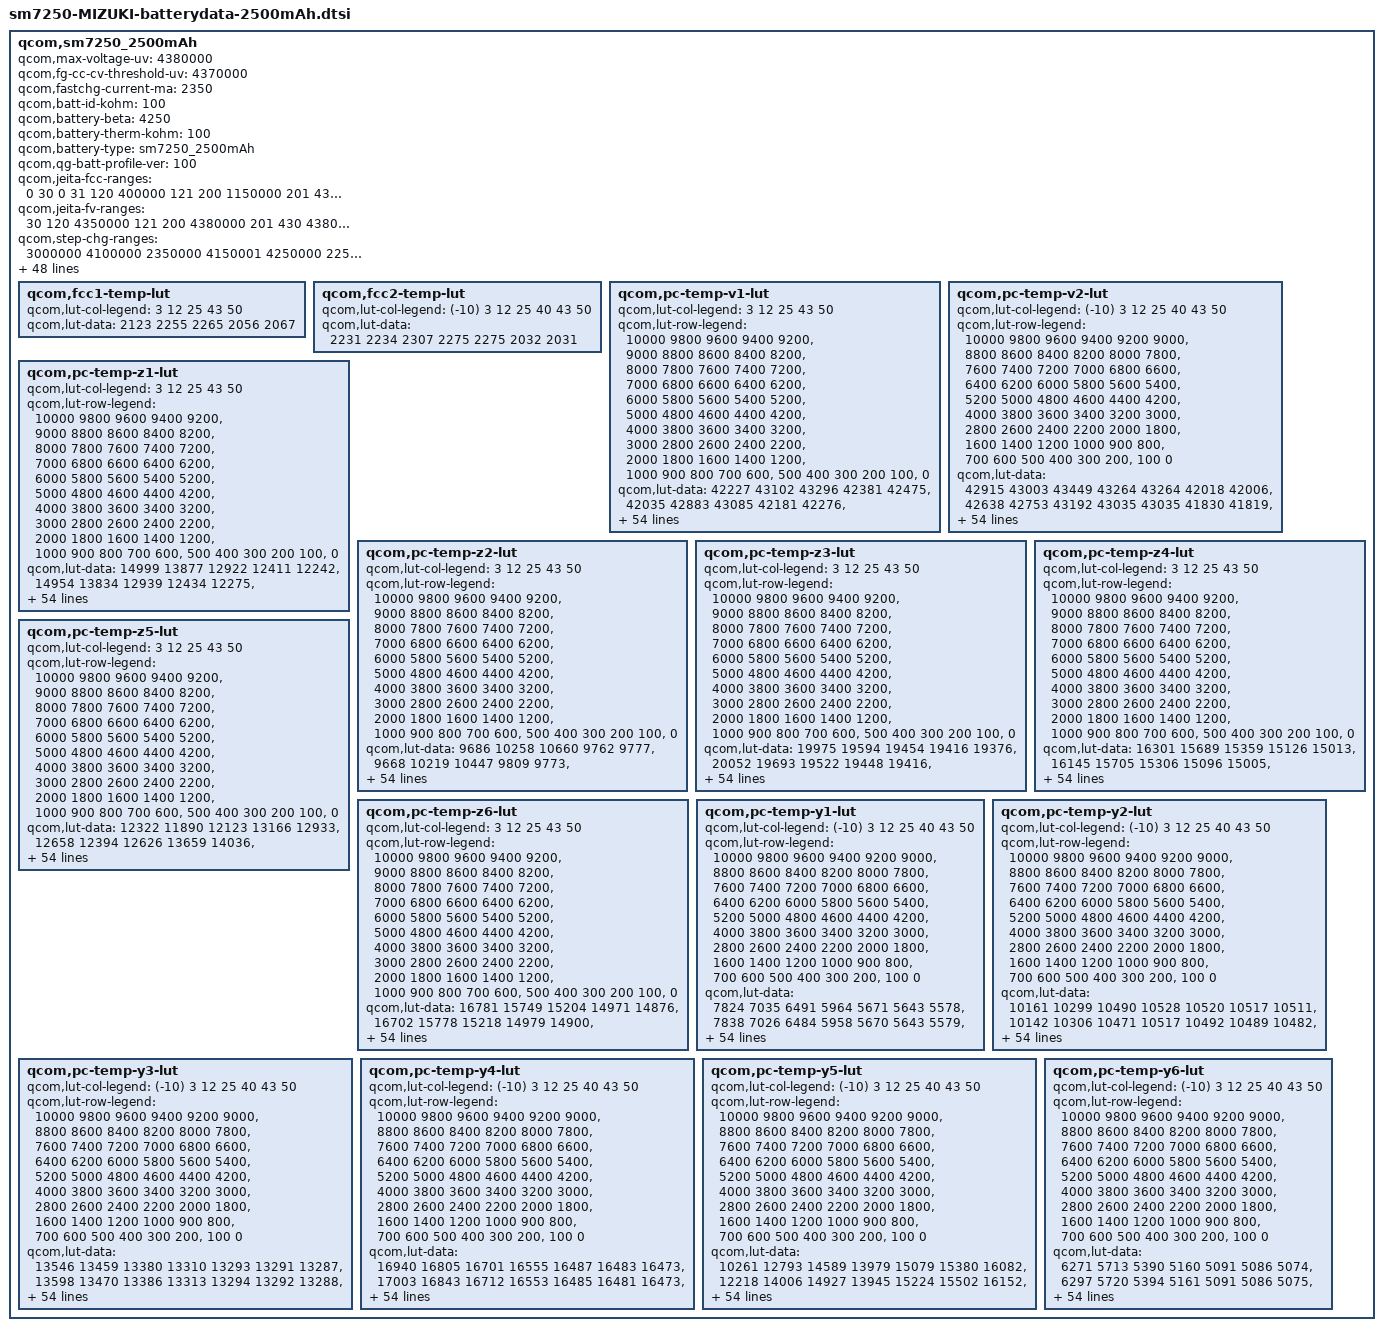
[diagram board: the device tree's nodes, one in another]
/*
 * This software is contributed or developed by KYOCERA Corporation.
 * (C) 2020 KYOCERA Corporation
 *
 * This program is free software; you can redistribute it and/or modify
 * it under the terms of the GNU General Public License version 2 and
 * only version 2 as published by the Free Software Foundation.
 *
 * This program is distributed in the hope that it will be useful,
 * but WITHOUT ANY WARRANTY; without even the implied warranty of
 * MERCHANTABILITY or FITNESS FOR A PARTICULAR PURPOSE.  See the
 * GNU General Public License for more details.
 */

qcom,sm7250_2500mAh {
	qcom,max-voltage-uv = <4380000>;
	qcom,fg-cc-cv-threshold-uv = <4370000>;
	qcom,fastchg-current-ma = <2350>;
	qcom,batt-id-kohm = <100>;
	qcom,battery-beta = <4250>;
	qcom,battery-therm-kohm = <100>;
	qcom,battery-type = "sm7250_2500mAh";
	qcom,qg-batt-profile-ver = <100>;

	qcom,jeita-fcc-ranges = <0  30  0
				 31 120  400000
				121 200  1150000
				201 430  2350000
				431 500  1150000
				501 600  0>;

	qcom,jeita-fv-ranges = <30 120  4350000
				121 200  4380000
				201 430  4380000
				431 500  4200000>;

	qcom,step-chg-ranges = <3000000  4100000  2350000
				4150001  4250000  2250000
				4250001  4380000  650000>;
	qcom,step-chg-ranges-cool = <3000000  4100000  400000
				4100001  4150000  400000
				4150001  4380000  400000>;
	qcom,step-chg-ranges-weekcool = <3000000  4100000  1150000
				4100001  4150000  850000
				4150001  4380000  650000>;
	qcom,step-chg-ranges-normal = <3000000  4150000  2350000
				4150001  4250000  1350000
				4250001  4380000  650000>;
	qcom,step-chg-ranges-warm = <3000000  4150000  1150000
				4150001  4250000  1150000
				4250001  4380000  1150000>;
	qcom,step-chg-temp-thresh = <30 100 200 430>;
	qcom,ocv-based-step-chg;

	/* COOL = 12 DegC, WARM = 43 DegC */
	qcom,jeita-soft-thresholds = <0x4A2A 0x22B8>;
	/* COLD = 3 DegC, HOT = 50 DegC */
	qcom,jeita-hard-thresholds = <0x5571 0x1C22>;
	/* COOL hys = 14 DegC, WARM hys = 38 DegC */
	qcom,jeita-soft-hys-thresholds = <0x477C 0x281D>;
	qcom,jeita-soft-fcc-ua = <400000 1150000>;
	qcom,jeita-soft-fv-uv = <4350000 4200000>;

	oem,batt-capacity-mah = <2175>;
	oem,deterioration-thresh-100 = <90>;
	oem,deterioration-thresh-90 = <80>;
	oem,deterioration-thresh-80 = <70>;
	oem,deterioration-thresh-70 = <60>;
	oem,deterioration-thresh-60 = <50>;
	oem,deterioration-thresh-50 = <40>;
	oem,deterioration-thresh-40 = <30>;
	oem,deterioration-thresh-30 = <20>;
	oem,deterioration-thresh-20 = <10>;
	oem,deterioration-thresh-90to100 = <95>;
	oem,deterioration-thresh-80to90 = <85>;
	oem,deterioration-thresh-70to80 = <75>;
	oem,deterioration-thresh-60to70 = <65>;
	oem,deterioration-thresh-50to60 = <55>;
	oem,deterioration-thresh-40to50 = <45>;
	oem,deterioration-thresh-30to40 = <35>;
	oem,deterioration-thresh-20to30 = <25>;
	oem,deterioration-thresh-10to20 = <15>;
	oem,cycle-count-thresh = <50 100 200 400 600>;
	oem,cycle-count-voltage-comp-mv = <40 80 120 160 200>;
	oem,cont-chg-thresh = <520000 840000 1200000 2200000 3300000>;
	oem,cont-chg-voltage-comp-mv = <40 80 120 160 200>;
	oem,batt-temp-thresh = <(-1250) 300 320 340 360 380 400 420 440 460>;
	oem,cont-chg-factor = <29 42 60 86 124 180 261 378 549 783>;
	oem,cont-chg-factor-batt-care = <15 21 30 43 62 90 131 189 275 392>;
	oem,batt-care-max-voltage-uv = <4200000>;

	qcom,fcc1-temp-lut {
		qcom,lut-col-legend = <3 12 25 43 50>;
		qcom,lut-data = <2123 2255 2265 2056 2067>;
	};

	qcom,fcc2-temp-lut {
		qcom,lut-col-legend = <(-10) 3 12 25 40 43 50>;
		qcom,lut-data = <2231 2234 2307 2275 2275 2032 2031>;
	};

	qcom,pc-temp-v1-lut {
		qcom,lut-col-legend = <3 12 25 43 50>;
		qcom,lut-row-legend = <10000 9800 9600 9400 9200>,
			<9000 8800 8600 8400 8200>,
			<8000 7800 7600 7400 7200>,
			<7000 6800 6600 6400 6200>,
			<6000 5800 5600 5400 5200>,
			<5000 4800 4600 4400 4200>,
			<4000 3800 3600 3400 3200>,
			<3000 2800 2600 2400 2200>,
			<2000 1800 1600 1400 1200>,
			<1000 900 800 700 600>,
			<500 400 300 200 100>,
			<0>;
		qcom,lut-data = <42227 43102 43296 42381 42475>,
			<42035 42883 43085 42181 42276>,
			<41846 42664 42864 41983 42077>,
			<41661 42447 42642 41790 41880>,
			<41479 42232 42423 41599 41683>,
			<41300 42022 42204 41411 41489>,
			<41126 41814 41989 41224 41299>,
			<40958 41612 41778 41041 41112>,
			<40797 41414 41570 40863 40931>,
			<40638 41220 41366 40693 40756>,
			<40476 41032 41165 40527 40586>,
			<40307 40848 40969 40367 40422>,
			<40140 40668 40779 40217 40265>,
			<39991 40493 40597 40071 40120>,
			<39869 40329 40420 39910 39963>,
			<39753 40172 40256 39697 39774>,
			<39613 40008 40097 39471 39562>,
			<39429 39830 39912 39284 39363>,
			<39225 39641 39676 39141 39203>,
			<39048 39445 39426 39024 39075>,
			<38914 39231 39227 38921 38962>,
			<38806 39032 39077 38826 38857>,
			<38722 38898 38955 38739 38761>,
			<38664 38819 38854 38657 38672>,
			<38620 38759 38769 38574 38586>,
			<38582 38700 38691 38495 38503>,
			<38541 38638 38613 38422 38425>,
			<38501 38576 38537 38355 38354>,
			<38462 38513 38465 38293 38288>,
			<38422 38448 38397 38234 38224>,
			<38382 38388 38334 38181 38165>,
			<38341 38336 38276 38130 38110>,
			<38304 38289 38223 38080 38053>,
			<38270 38245 38173 38032 37995>,
			<38233 38204 38125 37980 37934>,
			<38187 38164 38081 37923 37867>,
			<38122 38115 38030 37853 37793>,
			<38043 38045 37963 37772 37710>,
			<37955 37954 37875 37683 37619>,
			<37852 37853 37775 37587 37521>,
			<37736 37744 37668 37480 37411>,
			<37599 37621 37547 37358 37287>,
			<37463 37474 37407 37227 37153>,
			<37348 37325 37258 37119 37051>,
			<37259 37200 37138 37048 36986>,
			<37202 37131 37073 37007 36946>,
			<37172 37104 37054 36993 36931>,
			<37145 37087 37036 36967 36903>,
			<37103 37062 37005 36887 36811>,
			<36995 36978 36897 36673 36581>,
			<36723 36757 36604 36333 36228>,
			<36314 36375 36164 35893 35786>,
			<35798 35859 35604 35344 35228>,
			<35127 35181 34857 34613 34483>,
			<34098 34150 33671 33518 33374>,
			<31777 31771 30357 30356 30340>;
	};

	qcom,pc-temp-v2-lut {
		qcom,lut-col-legend = <(-10) 3 12 25 40 43 50>;
		qcom,lut-row-legend = <10000 9800 9600 9400 9200 9000>,
			<8800 8600 8400 8200 8000 7800>,
			<7600 7400 7200 7000 6800 6600>,
			<6400 6200 6000 5800 5600 5400>,
			<5200 5000 4800 4600 4400 4200>,
			<4000 3800 3600 3400 3200 3000>,
			<2800 2600 2400 2200 2000 1800>,
			<1600 1400 1200 1000 900 800>,
			<700 600 500 400 300 200>,
			<100 0>;
		qcom,lut-data = <42915 43003 43449 43264 43264 42018 42006>,
			<42638 42753 43192 43035 43035 41830 41819>,
			<42394 42522 42944 42809 42809 41644 41633>,
			<42167 42303 42707 42589 42589 41462 41452>,
			<41929 42085 42481 42374 42374 41282 41273>,
			<41674 41866 42261 42157 42157 41105 41097>,
			<41441 41652 42039 41943 41943 40933 40924>,
			<41275 41441 41820 41731 41731 40765 40755>,
			<41165 41234 41605 41524 41524 40602 40590>,
			<41054 41041 41394 41322 41322 40444 40432>,
			<40858 40876 41188 41122 41122 40292 40281>,
			<40544 40740 40990 40927 40927 40141 40131>,
			<40211 40600 40802 40736 40736 39988 39979>,
			<39974 40418 40620 40552 40552 39831 39823>,
			<39802 40181 40442 40376 40376 39670 39662>,
			<39634 39932 40270 40205 40205 39503 39495>,
			<39428 39705 40089 40032 40032 39314 39311>,
			<39196 39485 39876 39856 39856 39126 39126>,
			<38983 39281 39633 39674 39674 38969 38973>,
			<38800 39095 39404 39475 39475 38843 38849>,
			<38636 38924 39205 39252 39252 38737 38745>,
			<38507 38768 39028 39039 39039 38642 38650>,
			<38411 38626 38871 38879 38879 38552 38560>,
			<38333 38495 38733 38753 38753 38470 38477>,
			<38263 38373 38609 38641 38641 38394 38399>,
			<38199 38255 38497 38534 38534 38321 38326>,
			<38140 38148 38394 38436 38436 38253 38256>,
			<38084 38069 38299 38346 38346 38188 38191>,
			<38031 38015 38208 38260 38260 38127 38130>,
			<37980 37971 38119 38180 38180 38071 38073>,
			<37929 37934 38038 38109 38109 38015 38016>,
			<37877 37903 37964 38045 38045 37953 37946>,
			<37825 37872 37897 37985 37985 37883 37863>,
			<37770 37833 37843 37926 37926 37808 37773>,
			<37714 37786 37804 37868 37868 37730 37684>,
			<37654 37735 37771 37807 37807 37650 37599>,
			<37589 37681 37734 37738 37738 37567 37515>,
			<37517 37624 37690 37660 37660 37486 37435>,
			<37440 37559 37636 37580 37580 37412 37359>,
			<37356 37478 37566 37501 37501 37338 37284>,
			<37266 37380 37473 37421 37421 37257 37201>,
			<37178 37270 37364 37329 37329 37159 37102>,
			<37098 37147 37241 37214 37214 37047 36989>,
			<37024 37015 37099 37086 37086 36948 36890>,
			<36951 36902 36969 36983 36983 36903 36847>,
			<36877 36822 36879 36920 36920 36873 36820>,
			<36840 36790 36844 36892 36892 36856 36804>,
			<36796 36754 36806 36864 36864 36831 36778>,
			<36739 36706 36758 36833 36833 36795 36733>,
			<36662 36642 36698 36798 36798 36726 36643>,
			<36554 36551 36610 36740 36740 36620 36510>,
			<36393 36404 36466 36598 36598 36405 36274>,
			<36128 36128 36170 36264 36264 36054 35903>,
			<35676 35648 35667 35792 35792 35586 35415>,
			<35075 35024 35032 35203 35203 35030 34837>,
			<34251 34187 34190 34455 34455 34338 34125>;
	};

	qcom,pc-temp-z1-lut {
		qcom,lut-col-legend = <3 12 25 43 50>;
		qcom,lut-row-legend = <10000 9800 9600 9400 9200>,
			<9000 8800 8600 8400 8200>,
			<8000 7800 7600 7400 7200>,
			<7000 6800 6600 6400 6200>,
			<6000 5800 5600 5400 5200>,
			<5000 4800 4600 4400 4200>,
			<4000 3800 3600 3400 3200>,
			<3000 2800 2600 2400 2200>,
			<2000 1800 1600 1400 1200>,
			<1000 900 800 700 600>,
			<500 400 300 200 100>,
			<0>;
		qcom,lut-data = <14999 13877 12922 12411 12242>,
			<14954 13834 12939 12434 12275>,
			<14931 13826 12938 12444 12293>,
			<14919 13822 12929 12443 12295>,
			<14910 13818 12920 12440 12294>,
			<14901 13815 12913 12438 12294>,
			<14884 13813 12906 12435 12294>,
			<14864 13798 12899 12433 12295>,
			<14850 13775 12890 12431 12296>,
			<14836 13759 12882 12430 12297>,
			<14823 13745 12881 12430 12297>,
			<14807 13734 12883 12429 12297>,
			<14790 13723 12884 12429 12298>,
			<14776 13710 12884 12429 12298>,
			<14766 13701 12884 12431 12299>,
			<14756 13700 12885 12433 12301>,
			<14744 13701 12886 12436 12303>,
			<14717 13700 12888 12438 12306>,
			<14684 13699 12892 12441 12309>,
			<14669 13699 12896 12443 12311>,
			<14664 13701 12902 12446 12313>,
			<14661 13710 12909 12450 12316>,
			<14664 13718 12920 12453 12320>,
			<14681 13723 12928 12457 12325>,
			<14695 13729 12935 12462 12330>,
			<14692 13733 12941 12468 12334>,
			<14681 13736 12946 12475 12338>,
			<14673 13739 12952 12481 12343>,
			<14672 13739 12958 12488 12349>,
			<14671 13734 12965 12495 12355>,
			<14670 13729 12973 12501 12361>,
			<14668 13730 12980 12507 12366>,
			<14668 13738 12985 12513 12371>,
			<14670 13749 12990 12518 12375>,
			<14676 13757 12997 12523 12379>,
			<14684 13763 13007 12529 12384>,
			<14693 13771 13019 12535 12388>,
			<14705 13785 13029 12541 12393>,
			<14719 13805 13038 12549 12398>,
			<14734 13817 13047 12557 12403>,
			<14754 13820 13061 12563 12408>,
			<14766 13823 13078 12570 12414>,
			<14761 13848 13093 12578 12419>,
			<14763 13869 13107 12587 12424>,
			<14771 13853 13124 12600 12433>,
			<14765 13856 13120 12601 12433>,
			<14765 13851 13121 12601 12435>,
			<14786 13835 13122 12604 12436>,
			<14769 13846 13124 12609 12440>,
			<14816 13857 13142 12618 12449>,
			<14837 13871 13167 12630 12457>,
			<14839 13897 13179 12646 12473>,
			<14868 13931 13205 12667 12494>,
			<14928 13983 13245 12700 12524>,
			<14928 13983 13245 12700 12524>,
			<14928 13983 13245 12700 12524>;
	};

	qcom,pc-temp-z2-lut {
		qcom,lut-col-legend = <3 12 25 43 50>;
		qcom,lut-row-legend = <10000 9800 9600 9400 9200>,
			<9000 8800 8600 8400 8200>,
			<8000 7800 7600 7400 7200>,
			<7000 6800 6600 6400 6200>,
			<6000 5800 5600 5400 5200>,
			<5000 4800 4600 4400 4200>,
			<4000 3800 3600 3400 3200>,
			<3000 2800 2600 2400 2200>,
			<2000 1800 1600 1400 1200>,
			<1000 900 800 700 600>,
			<500 400 300 200 100>,
			<0>;
		qcom,lut-data = <9686 10258 10660 9762 9777>,
			<9668 10219 10447 9809 9773>,
			<9652 9959 10228 9850 9765>,
			<9638 9747 9984 9962 9744>,
			<9627 9722 9822 10149 9709>,
			<9618 9710 9790 10204 9685>,
			<9611 9702 9771 10018 9671>,
			<9606 9695 9761 9801 9661>,
			<9605 9690 9819 9789 9661>,
			<9605 9690 9919 9936 9668>,
			<9606 9691 9973 10072 9678>,
			<9609 9695 10002 10122 9691>,
			<9615 9702 10028 10158 9706>,
			<9621 9720 10059 10172 9720>,
			<9627 9738 10094 10173 9732>,
			<9634 9751 10113 10170 9743>,
			<9644 9762 10024 10115 9752>,
			<9658 9768 9869 9908 9760>,
			<9675 9771 9830 9771 9769>,
			<9690 9772 9880 9823 9777>,
			<9706 9773 9927 9897 9787>,
			<9718 9774 9913 9908 9798>,
			<9723 9776 9855 9846 9813>,
			<9724 9776 9820 9789 9829>,
			<9726 9774 9823 9789 9842>,
			<9727 9774 9831 9808 9857>,
			<9729 9782 9844 9832 9864>,
			<9730 9797 9880 9878 9851>,
			<9734 9808 9913 9929 9817>,
			<9741 9816 9915 9937 9784>,
			<9748 9823 9902 9879 9743>,
			<9755 9824 9890 9816 9711>,
			<9762 9820 9880 9794 9712>,
			<9768 9816 9870 9780 9737>,
			<9771 9816 9867 9774 9767>,
			<9774 9818 9878 9790 9801>,
			<9777 9821 9895 9820 9839>,
			<9782 9826 9911 9846 9869>,
			<9786 9833 9931 9871 9895>,
			<9789 9838 9943 9896 9912>,
			<9792 9839 9940 9921 9910>,
			<9796 9839 9931 9943 9895>,
			<9814 9845 9927 9934 9882>,
			<9792 9875 9924 9899 9869>,
			<9748 10007 9991 9913 9882>,
			<9581 9984 9972 9896 9872>,
			<9441 9980 9944 9898 9877>,
			<9502 9983 9941 9901 9889>,
			<9515 9988 9937 9930 9922>,
			<9513 10021 9962 9951 9907>,
			<9476 10052 10017 9859 9767>,
			<9403 10058 10018 9774 9703>,
			<9362 10041 9971 9743 9682>,
			<9334 9941 9917 9708 9652>,
			<9334 9941 9917 9708 9652>,
			<9334 9941 9917 9708 9652>;
	};

	qcom,pc-temp-z3-lut {
		qcom,lut-col-legend = <3 12 25 43 50>;
		qcom,lut-row-legend = <10000 9800 9600 9400 9200>,
			<9000 8800 8600 8400 8200>,
			<8000 7800 7600 7400 7200>,
			<7000 6800 6600 6400 6200>,
			<6000 5800 5600 5400 5200>,
			<5000 4800 4600 4400 4200>,
			<4000 3800 3600 3400 3200>,
			<3000 2800 2600 2400 2200>,
			<2000 1800 1600 1400 1200>,
			<1000 900 800 700 600>,
			<500 400 300 200 100>,
			<0>;
		qcom,lut-data = <19975 19594 19454 19416 19376>,
			<20052 19693 19522 19448 19416>,
			<20093 19770 19569 19474 19440>,
			<20122 19817 19607 19501 19448>,
			<20141 19838 19625 19530 19453>,
			<20144 19851 19626 19538 19454>,
			<20144 19854 19624 19525 19454>,
			<20143 19850 19622 19510 19454>,
			<20140 19845 19626 19504 19451>,
			<20134 19838 19633 19503 19445>,
			<20129 19828 19629 19504 19439>,
			<20124 19818 19616 19499 19435>,
			<20117 19810 19601 19491 19431>,
			<20112 19803 19592 19483 19426>,
			<20106 19795 19585 19474 19417>,
			<20094 19773 19575 19464 19408>,
			<20082 19746 19554 19450 19401>,
			<20062 19738 19531 19429 19395>,
			<20044 19761 19529 19418 19392>,
			<20043 19788 19560 19430 19395>,
			<20068 19794 19588 19451 19401>,
			<20096 19789 19583 19453 19402>,
			<20098 19781 19556 19425 19382>,
			<20084 19768 19532 19398 19360>,
			<20065 19748 19517 19394 19360>,
			<20049 19735 19506 19394 19376>,
			<20032 19733 19504 19394 19397>,
			<20016 19732 19522 19424 19421>,
			<20004 19732 19545 19469 19447>,
			<19992 19743 19560 19481 19455>,
			<19984 19758 19571 19478 19446>,
			<19980 19762 19577 19471 19433>,
			<19977 19757 19572 19462 19421>,
			<19974 19749 19561 19447 19407>,
			<19969 19743 19551 19436 19399>,
			<19962 19737 19543 19432 19398>,
			<19954 19731 19536 19428 19397>,
			<19943 19723 19530 19424 19396>,
			<19930 19716 19524 19418 19391>,
			<19916 19707 19519 19413 19385>,
			<19900 19699 19515 19416 19388>,
			<19879 19689 19511 19425 19401>,
			<19850 19674 19503 19424 19404>,
			<19710 19642 19488 19410 19403>,
			<19480 19571 19460 19394 19389>,
			<19340 19559 19462 19393 19376>,
			<19276 19560 19454 19387 19367>,
			<19272 19495 19451 19379 19359>,
			<19271 19513 19437 19373 19356>,
			<19271 19516 19422 19374 19371>,
			<19272 19444 19412 19405 19404>,
			<19276 19380 19397 19422 19406>,
			<19278 19365 19402 19424 19406>,
			<19279 19360 19406 19425 19409>,
			<19279 19360 19406 19425 19409>,
			<19279 19360 19406 19425 19409>;
	};

	qcom,pc-temp-z4-lut {
		qcom,lut-col-legend = <3 12 25 43 50>;
		qcom,lut-row-legend = <10000 9800 9600 9400 9200>,
			<9000 8800 8600 8400 8200>,
			<8000 7800 7600 7400 7200>,
			<7000 6800 6600 6400 6200>,
			<6000 5800 5600 5400 5200>,
			<5000 4800 4600 4400 4200>,
			<4000 3800 3600 3400 3200>,
			<3000 2800 2600 2400 2200>,
			<2000 1800 1600 1400 1200>,
			<1000 900 800 700 600>,
			<500 400 300 200 100>,
			<0>;
		qcom,lut-data = <16301 15689 15359 15126 15013>,
			<16145 15705 15306 15096 15005>,
			<15983 15574 15237 15053 14989>,
			<15811 15443 15156 14985 14961>,
			<15654 15340 15084 14904 14920>,
			<15533 15248 15029 14863 14883>,
			<15430 15173 14983 14846 14852>,
			<15346 15113 14939 14835 14826>,
			<15280 15062 14881 14819 14805>,
			<15225 15020 14824 14775 14786>,
			<15178 14984 14795 14739 14771>,
			<15132 14953 14778 14727 14758>,
			<15090 14921 14766 14717 14748>,
			<15073 14889 14758 14710 14740>,
			<15075 14875 14751 14704 14733>,
			<15079 14878 14746 14700 14728>,
			<15078 14883 14751 14700 14723>,
			<15037 14889 14768 14712 14717>,
			<14982 14895 14797 14731 14714>,
			<14971 14905 14863 14788 14754>,
			<15012 14934 14934 14869 14842>,
			<15067 15034 14983 14922 14900>,
			<15101 15123 15029 14962 14934>,
			<15128 15129 15049 14986 14956>,
			<15145 15111 15045 14984 14951>,
			<15142 15090 15034 14967 14916>,
			<15122 15065 15018 14943 14872>,
			<15098 15036 14980 14889 14823>,
			<15078 15008 14935 14819 14772>,
			<15058 14980 14899 14784 14746>,
			<15039 14955 14864 14766 14734>,
			<15023 14939 14842 14756 14728>,
			<15008 14929 14835 14755 14727>,
			<14994 14921 14831 14756 14728>,
			<14980 14914 14830 14757 14729>,
			<14967 14906 14832 14760 14732>,
			<14955 14901 14834 14768 14740>,
			<14945 14900 14839 14777 14749>,
			<14935 14900 14851 14796 14765>,
			<14920 14899 14859 14811 14779>,
			<14900 14880 14849 14804 14774>,
			<14877 14848 14825 14780 14752>,
			<14849 14827 14812 14777 14748>,
			<14887 14798 14801 14783 14751>,
			<14968 14745 14747 14746 14722>,
			<15115 14733 14723 14727 14713>,
			<15180 14717 14707 14709 14698>,
			<15164 14769 14686 14684 14674>,
			<15160 14737 14686 14674 14659>,
			<15155 14740 14718 14687 14660>,
			<15171 14841 14766 14699 14672>,
			<15183 14921 14787 14685 14675>,
			<15188 14943 14782 14686 14676>,
			<15203 14954 14779 14685 14674>,
			<15203 14954 14779 14685 14674>,
			<15203 14954 14779 14685 14674>;
	};

	qcom,pc-temp-z5-lut {
		qcom,lut-col-legend = <3 12 25 43 50>;
		qcom,lut-row-legend = <10000 9800 9600 9400 9200>,
			<9000 8800 8600 8400 8200>,
			<8000 7800 7600 7400 7200>,
			<7000 6800 6600 6400 6200>,
			<6000 5800 5600 5400 5200>,
			<5000 4800 4600 4400 4200>,
			<4000 3800 3600 3400 3200>,
			<3000 2800 2600 2400 2200>,
			<2000 1800 1600 1400 1200>,
			<1000 900 800 700 600>,
			<500 400 300 200 100>,
			<0>;
		qcom,lut-data = <12322 11890 12123 13166 12933>,
			<12658 12394 12626 13659 14036>,
			<12986 13052 13208 14178 14693>,
			<13334 13703 13891 15017 14855>,
			<13709 14262 14459 16176 14935>,
			<14094 14782 14817 16712 15047>,
			<14487 15283 15075 16563 15250>,
			<14902 15780 15310 16251 15505>,
			<15358 16284 16468 16623 15800>,
			<15838 16805 18246 18982 16226>,
			<16336 17304 19432 21241 16721>,
			<16928 17925 20350 22410 17321>,
			<17661 19209 21107 23406 17963>,
			<18294 21329 21709 23856 18221>,
			<18844 22548 22282 23667 18204>,
			<19360 21621 22648 23034 18169>,
			<19682 19808 21604 21834 18276>,
			<19931 19373 19747 19567 18749>,
			<20297 24122 20434 18395 19330>,
			<21725 30053 27893 21155 19960>,
			<29452 31239 34684 25303 20597>,
			<37578 30048 32973 25872 20638>,
			<38697 28289 25693 20918 17709>,
			<36532 26055 20106 15816 14268>,
			<33732 22892 17898 14447 13677>,
			<31377 20844 16409 13751 13683>,
			<28928 20449 16090 13518 13763>,
			<27086 20229 16565 14657 14959>,
			<26146 20208 17415 16851 17369>,
			<25451 21685 18697 18570 18924>,
			<25159 24053 20956 20044 19791>,
			<25469 25452 22939 21095 20356>,
			<26152 26286 24157 21468 20535>,
			<26679 26856 25118 21697 20609>,
			<26961 27101 25399 21797 20696>,
			<27194 27268 25269 21815 21047>,
			<27404 27343 25000 21813 21546>,
			<27636 27114 24430 21594 21549>,
			<27814 26536 22855 19626 19315>,
			<27740 25999 21396 17682 16898>,
			<26935 25512 20834 17704 16946>,
			<26282 24964 20422 18298 18061>,
			<26103 24237 19489 17859 18208>,
			<23071 23983 18489 16322 17838>,
			<17249 25497 20219 16604 17528>,
			<11322 22524 21399 17134 16245>,
			<10828 22979 20901 17116 16210>,
			<10787 17107 21998 18250 17743>,
			<10771 17957 20437 18965 19337>,
			<10798 17190 16259 16868 20033>,
			<10791 13453 13911 16506 20386>,
			<10763 11706 12739 17909 19193>,
			<10730 11433 12722 17458 18232>,
			<10691 11582 12695 16954 17981>,
			<10691 11582 12695 16954 17981>,
			<10691 11582 12695 16954 17981>;
	};

	qcom,pc-temp-z6-lut {
		qcom,lut-col-legend = <3 12 25 43 50>;
		qcom,lut-row-legend = <10000 9800 9600 9400 9200>,
			<9000 8800 8600 8400 8200>,
			<8000 7800 7600 7400 7200>,
			<7000 6800 6600 6400 6200>,
			<6000 5800 5600 5400 5200>,
			<5000 4800 4600 4400 4200>,
			<4000 3800 3600 3400 3200>,
			<3000 2800 2600 2400 2200>,
			<2000 1800 1600 1400 1200>,
			<1000 900 800 700 600>,
			<500 400 300 200 100>,
			<0>;
		qcom,lut-data = <16781 15749 15204 14971 14876>,
			<16702 15778 15218 14979 14900>,
			<16615 15741 15213 14980 14910>,
			<16516 15704 15190 14970 14904>,
			<16422 15663 15165 14952 14889>,
			<16344 15617 15142 14936 14875>,
			<16274 15574 15118 14923 14863>,
			<16214 15537 15095 14909 14852>,
			<16168 15503 15072 14893 14841>,
			<16129 15473 15051 14877 14829>,
			<16095 15446 15034 14863 14819>,
			<16061 15422 15018 14854 14811>,
			<16031 15399 15006 14846 14804>,
			<16009 15378 14997 14838 14797>,
			<15994 15361 14989 14829 14789>,
			<15982 15348 14983 14822 14782>,
			<15963 15337 14976 14816 14776>,
			<15924 15335 14972 14811 14770>,
			<15885 15346 14977 14809 14767>,
			<15878 15367 15024 14841 14788>,
			<15908 15393 15072 14890 14831>,
			<15942 15435 15085 14907 14851>,
			<15951 15468 15093 14909 14854>,
			<15954 15467 15096 14911 14857>,
			<15955 15453 15091 14909 14856>,
			<15950 15437 15080 14902 14850>,
			<15932 15424 15073 14895 14843>,
			<15913 15413 15067 14889 14837>,
			<15900 15405 15062 14883 14830>,
			<15887 15400 15057 14876 14823>,
			<15878 15397 15050 14869 14815>,
			<15872 15393 15044 14861 14806>,
			<15867 15388 15037 14854 14799>,
			<15863 15383 15031 14846 14792>,
			<15858 15381 15029 14843 14789>,
			<15854 15379 15028 14844 14790>,
			<15852 15378 15027 14845 14792>,
			<15851 15379 15028 14846 14795>,
			<15851 15384 15033 14852 14799>,
			<15849 15386 15037 14857 14803>,
			<15845 15382 15034 14856 14803>,
			<15839 15374 15025 14853 14801>,
			<15828 15366 15019 14851 14801>,
			<15789 15350 15012 14848 14804>,
			<15734 15305 14982 14826 14785>,
			<15726 15295 14974 14818 14775>,
			<15726 15290 14963 14807 14764>,
			<15724 15279 14953 14792 14749>,
			<15728 15280 14948 14785 14741>,
			<15738 15291 14956 14792 14749>,
			<15759 15307 14977 14816 14777>,
			<15782 15322 14986 14824 14783>,
			<15806 15338 14994 14830 14789>,
			<15845 15364 15006 14837 14796>,
			<15845 15364 15006 14837 14796>,
			<15845 15364 15006 14837 14796>;
	};

	qcom,pc-temp-y1-lut {
		qcom,lut-col-legend = <(-10) 3 12 25 40 43 50>;
		qcom,lut-row-legend = <10000 9800 9600 9400 9200 9000>,
			<8800 8600 8400 8200 8000 7800>,
			<7600 7400 7200 7000 6800 6600>,
			<6400 6200 6000 5800 5600 5400>,
			<5200 5000 4800 4600 4400 4200>,
			<4000 3800 3600 3400 3200 3000>,
			<2800 2600 2400 2200 2000 1800>,
			<1600 1400 1200 1000 900 800>,
			<700 600 500 400 300 200>,
			<100 0>;
		qcom,lut-data = <7824 7035 6491 5964 5671 5643 5578>,
			<7838 7026 6484 5958 5670 5643 5579>,
			<7855 7020 6478 5952 5668 5641 5579>,
			<7872 7018 6472 5947 5666 5640 5579>,
			<7886 7019 6465 5942 5664 5639 5579>,
			<7893 7020 6460 5937 5663 5638 5579>,
			<7894 7023 6454 5934 5661 5636 5578>,
			<7890 7030 6448 5931 5660 5635 5577>,
			<7887 7036 6444 5929 5658 5634 5577>,
			<7883 7036 6444 5927 5656 5632 5577>,
			<7878 7032 6446 5924 5653 5630 5577>,
			<7878 7029 6447 5923 5653 5631 5578>,
			<7891 7026 6445 5923 5653 5631 5579>,
			<7907 7023 6442 5923 5654 5632 5580>,
			<7909 7027 6442 5923 5655 5633 5580>,
			<7898 7044 6442 5924 5656 5633 5578>,
			<7888 7058 6444 5925 5658 5633 5576>,
			<7886 7059 6448 5927 5659 5634 5577>,
			<7884 7056 6457 5931 5661 5636 5578>,
			<7884 7054 6462 5935 5663 5638 5580>,
			<7887 7055 6461 5940 5664 5639 5581>,
			<7891 7057 6459 5946 5667 5642 5582>,
			<7893 7059 6460 5951 5669 5644 5584>,
			<7903 7064 6470 5956 5672 5647 5587>,
			<7916 7067 6480 5961 5675 5650 5590>,
			<7925 7064 6482 5965 5679 5653 5593>,
			<7941 7056 6482 5970 5682 5656 5596>,
			<7949 7051 6483 5975 5686 5660 5599>,
			<7939 7051 6483 5981 5690 5664 5602>,
			<7922 7052 6484 5987 5694 5667 5604>,
			<7915 7053 6484 5994 5698 5671 5607>,
			<7924 7059 6488 6001 5702 5674 5610>,
			<7937 7066 6494 6007 5706 5678 5614>,
			<7937 7072 6495 6011 5710 5682 5617>,
			<7917 7077 6495 6016 5715 5687 5621>,
			<7898 7079 6494 6021 5719 5690 5623>,
			<7899 7072 6498 6027 5722 5693 5626>,
			<7905 7059 6505 6033 5724 5695 5628>,
			<7908 7053 6512 6038 5727 5698 5630>,
			<7907 7055 6517 6044 5729 5700 5631>,
			<7904 7062 6523 6050 5732 5702 5633>,
			<7903 7069 6528 6061 5736 5706 5635>,
			<7906 7079 6535 6079 5740 5709 5638>,
			<7913 7088 6539 6093 5745 5714 5641>,
			<7928 7092 6536 6100 5750 5718 5644>,
			<7970 7089 6530 6108 5756 5723 5646>,
			<7999 7090 6530 6113 5757 5724 5647>,
			<8043 7097 6537 6119 5758 5725 5647>,
			<8115 7119 6548 6126 5758 5725 5647>,
			<8203 7152 6557 6135 5759 5726 5648>,
			<8292 7200 6566 6146 5762 5729 5651>,
			<8385 7276 6584 6154 5769 5736 5659>,
			<8499 7360 6621 6155 5781 5747 5669>,
			<8715 7458 6674 6174 5795 5763 5687>,
			<8715 7458 6674 6174 5795 5763 5687>,
			<8715 7458 6674 6174 5795 5763 5687>;
	};

	qcom,pc-temp-y2-lut {
		qcom,lut-col-legend = <(-10) 3 12 25 40 43 50>;
		qcom,lut-row-legend = <10000 9800 9600 9400 9200 9000>,
			<8800 8600 8400 8200 8000 7800>,
			<7600 7400 7200 7000 6800 6600>,
			<6400 6200 6000 5800 5600 5400>,
			<5200 5000 4800 4600 4400 4200>,
			<4000 3800 3600 3400 3200 3000>,
			<2800 2600 2400 2200 2000 1800>,
			<1600 1400 1200 1000 900 800>,
			<700 600 500 400 300 200>,
			<100 0>;
		qcom,lut-data = <10161 10299 10490 10528 10520 10517 10511>,
			<10142 10306 10471 10517 10492 10489 10482>,
			<10132 10310 10451 10502 10466 10462 10453>,
			<10131 10310 10430 10487 10441 10436 10425>,
			<10135 10308 10411 10471 10418 10413 10400>,
			<10144 10305 10397 10459 10398 10393 10380>,
			<10166 10298 10390 10450 10381 10377 10367>,
			<10222 10280 10384 10440 10364 10362 10357>,
			<10262 10268 10382 10435 10356 10354 10349>,
			<10261 10295 10383 10440 10360 10355 10344>,
			<10257 10356 10388 10452 10373 10363 10340>,
			<10256 10383 10395 10467 10390 10375 10339>,
			<10276 10381 10419 10485 10429 10406 10352>,
			<10306 10378 10455 10511 10473 10443 10374>,
			<10321 10383 10493 10551 10494 10464 10393>,
			<10328 10425 10544 10624 10502 10479 10425>,
			<10332 10464 10578 10676 10513 10499 10466>,
			<10228 10469 10575 10685 10564 10553 10528>,
			<9901 10470 10560 10691 10670 10653 10613>,
			<9696 10472 10552 10691 10723 10702 10654>,
			<9686 10477 10556 10665 10675 10657 10616>,
			<9680 10483 10564 10630 10601 10588 10559>,
			<9676 10482 10568 10622 10580 10569 10544>,
			<9672 10452 10571 10627 10587 10576 10549>,
			<9669 10421 10575 10634 10598 10585 10556>,
			<9668 10417 10584 10654 10613 10598 10563>,
			<9667 10419 10601 10689 10633 10617 10579>,
			<9666 10420 10611 10709 10648 10633 10599>,
			<9665 10407 10600 10714 10652 10647 10634>,
			<9664 10378 10578 10718 10655 10662 10677>,
			<9663 10354 10563 10724 10666 10674 10693>,
			<9662 10341 10556 10736 10763 10743 10696>,
			<9662 10325 10551 10747 10872 10820 10697>,
			<9661 10257 10543 10751 10871 10818 10693>,
			<9661 9981 10534 10753 10776 10746 10676>,
			<9660 9738 10524 10749 10690 10681 10659>,
			<9660 9699 10512 10725 10661 10655 10642>,
			<9659 9687 10497 10688 10642 10634 10616>,
			<9659 9679 10477 10663 10629 10618 10593>,
			<9658 9673 10442 10647 10622 10609 10580>,
			<9658 9668 10395 10630 10614 10600 10568>,
			<9657 9665 10346 10604 10606 10590 10553>,
			<9657 9663 10294 10565 10586 10571 10536>,
			<9656 9661 10224 10522 10556 10543 10512>,
			<9655 9659 10056 10467 10515 10499 10461>,
			<9653 9657 9784 10411 10473 10447 10386>,
			<9652 9656 9714 10395 10466 10438 10372>,
			<9651 9655 9693 10384 10467 10439 10373>,
			<9649 9654 9681 10373 10471 10442 10375>,
			<9648 9653 9672 10355 10468 10440 10375>,
			<9647 9651 9666 10327 10425 10403 10351>,
			<9646 9649 9660 10322 10380 10358 10307>,
			<9646 9647 9657 10334 10391 10354 10267>,
			<9646 9647 9653 10326 10356 10317 10225>,
			<9646 9647 9653 10326 10356 10317 10225>,
			<9646 9647 9653 10326 10356 10317 10225>;
	};

	qcom,pc-temp-y3-lut {
		qcom,lut-col-legend = <(-10) 3 12 25 40 43 50>;
		qcom,lut-row-legend = <10000 9800 9600 9400 9200 9000>,
			<8800 8600 8400 8200 8000 7800>,
			<7600 7400 7200 7000 6800 6600>,
			<6400 6200 6000 5800 5600 5400>,
			<5200 5000 4800 4600 4400 4200>,
			<4000 3800 3600 3400 3200 3000>,
			<2800 2600 2400 2200 2000 1800>,
			<1600 1400 1200 1000 900 800>,
			<700 600 500 400 300 200>,
			<100 0>;
		qcom,lut-data = <13546 13459 13380 13310 13293 13291 13287>,
			<13598 13470 13386 13313 13294 13292 13288>,
			<13632 13483 13392 13316 13296 13294 13290>,
			<13652 13495 13398 13319 13298 13296 13292>,
			<13662 13504 13404 13323 13300 13298 13294>,
			<13665 13510 13408 13325 13302 13300 13296>,
			<13660 13510 13411 13326 13304 13302 13297>,
			<13635 13508 13415 13327 13306 13304 13299>,
			<13615 13504 13417 13329 13308 13306 13301>,
			<13612 13495 13418 13333 13310 13308 13303>,
			<13611 13478 13418 13339 13311 13309 13305>,
			<13609 13472 13418 13341 13313 13311 13306>,
			<13602 13478 13406 13341 13317 13314 13307>,
			<13591 13486 13390 13341 13322 13318 13308>,
			<13579 13487 13388 13340 13323 13319 13309>,
			<13563 13482 13397 13338 13323 13320 13312>,
			<13552 13475 13405 13337 13322 13320 13314>,
			<13552 13465 13401 13336 13320 13318 13313>,
			<13553 13453 13389 13335 13315 13313 13309>,
			<13553 13441 13380 13333 13310 13309 13305>,
			<13548 13432 13375 13326 13303 13302 13298>,
			<13538 13424 13372 13319 13297 13295 13291>,
			<13535 13418 13369 13317 13294 13293 13289>,
			<13545 13415 13366 13317 13293 13292 13290>,
			<13562 13411 13364 13316 13293 13292 13290>,
			<13579 13403 13362 13316 13293 13292 13291>,
			<13599 13387 13359 13316 13294 13293 13291>,
			<13623 13377 13357 13315 13295 13294 13291>,
			<13656 13378 13358 13314 13294 13293 13291>,
			<13697 13382 13358 13314 13294 13293 13291>,
			<13738 13387 13358 13313 13294 13293 13290>,
			<13775 13397 13356 13313 13296 13294 13290>,
			<13813 13410 13354 13313 13299 13296 13290>,
			<13859 13422 13355 13314 13299 13296 13290>,
			<13917 13434 13359 13315 13296 13294 13289>,
			<13980 13450 13363 13316 13293 13292 13288>,
			<14044 13471 13367 13315 13293 13292 13288>,
			<14110 13500 13370 13314 13293 13292 13288>,
			<14177 13533 13372 13314 13293 13292 13288>,
			<14239 13566 13373 13315 13294 13293 13290>,
			<14302 13603 13375 13316 13295 13294 13293>,
			<14381 13653 13377 13318 13296 13295 13293>,
			<14480 13720 13382 13319 13295 13294 13291>,
			<14609 13809 13390 13322 13295 13293 13289>,
			<14781 13923 13407 13329 13299 13297 13292>,
			<15064 14084 13445 13343 13311 13309 13303>,
			<15295 14191 13472 13354 13316 13313 13306>,
			<15749 14318 13509 13369 13319 13316 13308>,
			<16740 14490 13560 13383 13322 13318 13309>,
			<18306 14751 13624 13386 13322 13318 13309>,
			<20839 15269 13706 13381 13319 13316 13308>,
			<26596 16558 13829 13373 13317 13314 13308>,
			<37842 18953 13991 13367 13320 13317 13310>,
			<65535 26004 14578 13382 13324 13322 13316>,
			<65535 26004 14578 13382 13324 13322 13316>,
			<65535 26004 14578 13382 13324 13322 13316>;
	};

	qcom,pc-temp-y4-lut {
		qcom,lut-col-legend = <(-10) 3 12 25 40 43 50>;
		qcom,lut-row-legend = <10000 9800 9600 9400 9200 9000>,
			<8800 8600 8400 8200 8000 7800>,
			<7600 7400 7200 7000 6800 6600>,
			<6400 6200 6000 5800 5600 5400>,
			<5200 5000 4800 4600 4400 4200>,
			<4000 3800 3600 3400 3200 3000>,
			<2800 2600 2400 2200 2000 1800>,
			<1600 1400 1200 1000 900 800>,
			<700 600 500 400 300 200>,
			<100 0>;
		qcom,lut-data = <16940 16805 16701 16555 16487 16483 16473>,
			<17003 16843 16712 16553 16485 16481 16473>,
			<17067 16881 16726 16553 16484 16481 16473>,
			<17127 16917 16739 16553 16483 16480 16473>,
			<17181 16949 16751 16554 16484 16481 16473>,
			<17225 16975 16760 16555 16485 16481 16473>,
			<17255 16993 16764 16558 16487 16483 16474>,
			<17274 17005 16766 16565 16490 16486 16475>,
			<17300 17020 16768 16572 16493 16489 16478>,
			<17387 17051 16775 16576 16499 16494 16481>,
			<17529 17100 16789 16579 16506 16500 16486>,
			<17586 17150 16812 16585 16512 16506 16492>,
			<17418 17211 16884 16599 16516 16511 16500>,
			<17180 17263 16964 16620 16520 16517 16510>,
			<17104 17261 16979 16644 16529 16526 16519>,
			<17092 17169 16969 16677 16550 16544 16529>,
			<17080 17057 16950 16702 16574 16564 16539>,
			<17052 16984 16907 16712 16595 16583 16556>,
			<17003 16922 16822 16715 16615 16604 16577>,
			<16957 16869 16751 16708 16622 16612 16587>,
			<16914 16824 16705 16644 16581 16573 16555>,
			<16877 16785 16669 16564 16519 16515 16505>,
			<16867 16745 16651 16546 16501 16497 16489>,
			<16872 16700 16640 16543 16502 16498 16488>,
			<16879 16663 16634 16542 16504 16499 16488>,
			<16883 16645 16632 16544 16508 16503 16491>,
			<16887 16632 16631 16552 16519 16513 16500>,
			<16888 16626 16630 16562 16533 16527 16512>,
			<16885 16633 16619 16573 16549 16542 16525>,
			<16879 16649 16600 16586 16568 16560 16540>,
			<16877 16664 16589 16600 16580 16573 16555>,
			<16882 16674 16587 16618 16589 16584 16572>,
			<16891 16686 16585 16630 16594 16592 16586>,
			<16896 16710 16589 16629 16593 16590 16584>,
			<16898 16764 16615 16623 16582 16576 16561>,
			<16899 16814 16647 16614 16567 16558 16536>,
			<16897 16835 16675 16591 16547 16540 16522>,
			<16891 16848 16703 16562 16522 16518 16510>,
			<16888 16854 16716 16554 16511 16510 16506>,
			<16891 16851 16718 16560 16512 16510 16505>,
			<16900 16843 16720 16567 16513 16510 16504>,
			<16912 16831 16718 16569 16511 16508 16501>,
			<16934 16802 16704 16570 16498 16494 16485>,
			<16968 16776 16689 16571 16485 16481 16471>,
			<17018 16785 16703 16583 16492 16490 16484>,
			<17119 16847 16768 16615 16526 16530 16539>,
			<17198 16886 16809 16644 16547 16552 16563>,
			<17344 16928 16871 16698 16581 16581 16580>,
			<17625 16978 16942 16748 16614 16607 16591>,
			<18043 17044 16983 16760 16624 16613 16587>,
			<18627 17150 16987 16725 16580 16570 16546>,
			<19882 17447 16982 16667 16534 16527 16512>,
			<23287 18166 16960 16642 16529 16525 16515>,
			<46562 22503 17090 16717 16588 16592 16601>,
			<46562 22503 17090 16717 16588 16592 16601>,
			<46562 22503 17090 16717 16588 16592 16601>;
	};

	qcom,pc-temp-y5-lut {
		qcom,lut-col-legend = <(-10) 3 12 25 40 43 50>;
		qcom,lut-row-legend = <10000 9800 9600 9400 9200 9000>,
			<8800 8600 8400 8200 8000 7800>,
			<7600 7400 7200 7000 6800 6600>,
			<6400 6200 6000 5800 5600 5400>,
			<5200 5000 4800 4600 4400 4200>,
			<4000 3800 3600 3400 3200 3000>,
			<2800 2600 2400 2200 2000 1800>,
			<1600 1400 1200 1000 900 800>,
			<700 600 500 400 300 200>,
			<100 0>;
		qcom,lut-data = <10261 12793 14589 13979 15079 15380 16082>,
			<12218 14006 14927 13945 15224 15502 16152>,
			<13519 14811 15142 13896 15287 15557 16187>,
			<14297 15291 15261 13835 15284 15556 16192>,
			<14684 15528 15313 13764 15234 15516 16175>,
			<14811 15606 15326 13684 15152 15450 16144>,
			<14640 15542 15276 13512 15040 15354 16086>,
			<13835 15180 15039 13119 14856 15181 15938>,
			<13227 14697 14772 12872 14628 14960 15736>,
			<14028 14043 14560 12996 14279 14638 15474>,
			<15907 13235 14320 13236 13861 14238 15117>,
			<16815 12952 14032 13304 13713 14016 14722>,
			<16794 14460 13527 12931 13972 14028 14160>,
			<16738 16640 13054 12492 14302 14109 13659>,
			<16848 17568 13342 12416 14255 14049 13568>,
			<17486 17965 15697 12428 13611 13606 13595>,
			<18062 18213 17826 12459 13074 13244 13642>,
			<17539 18352 18107 13197 13264 13421 13786>,
			<15593 18447 18198 14943 13940 14008 14166>,
			<13842 18554 18270 16095 14596 14589 14573>,
			<12782 18737 18367 16625 15252 15195 15063>,
			<11933 18991 18451 16968 15836 15746 15537>,
			<11589 19329 18459 16999 15876 15805 15639>,
			<11475 20132 18365 16872 15167 15255 15461>,
			<11405 20890 18267 16692 14414 14638 15161>,
			<11380 19996 18281 16434 14182 14353 14751>,
			<11411 15864 18410 16039 14054 14074 14119>,
			<11479 12887 18617 15723 13954 13867 13664>,
			<11654 12828 19248 15497 13825 13727 13498>,
			<11958 12916 20202 15327 13692 13601 13390>,
			<12183 13087 20467 15304 13714 13609 13363>,
			<12301 13994 18823 15508 14503 14194 13472>,
			<12404 15053 16808 15840 15415 14893 13674>,
			<12539 15085 16363 16395 15520 15039 13918>,
			<12780 13981 16330 17293 15338 15026 14297>,
			<12981 13016 16302 17758 15220 15037 14610>,
			<13021 13024 16192 17358 15369 15213 14850>,
			<13009 13265 15989 16525 15696 15546 15195>,
			<12962 13412 15758 15829 15834 15725 15472>,
			<12586 13405 15411 15239 15608 15739 16043>,
			<12002 13365 15065 14757 15300 15706 16652>,
			<11807 13284 15014 14484 15230 15682 16737>,
			<11872 13041 15356 14305 15252 15587 16368>,
			<11966 12801 15704 14179 15268 15430 15807>,
			<12028 12695 15079 13943 15110 15096 15063>,
			<12062 12557 13223 13601 14555 14384 13985>,
			<12042 12503 12757 13530 14219 14034 13603>,
			<11840 12490 12674 13506 13759 13616 13283>,
			<11302 12510 12634 13526 13278 13212 13059>,
			<10652 12517 12597 13636 13059 13065 13078>,
			<10075 12260 12552 14158 13666 13830 14211>,
			<9525 11230 12580 15408 15814 15974 16348>,
			<9111 10135 12810 17456 19681 19418 18804>,
			<8863 9291 12546 19196 21574 21676 21913>,
			<8863 9291 12546 19196 21574 21676 21913>,
			<8863 9291 12546 19196 21574 21676 21913>;
	};

	qcom,pc-temp-y6-lut {
		qcom,lut-col-legend = <(-10) 3 12 25 40 43 50>;
		qcom,lut-row-legend = <10000 9800 9600 9400 9200 9000>,
			<8800 8600 8400 8200 8000 7800>,
			<7600 7400 7200 7000 6800 6600>,
			<6400 6200 6000 5800 5600 5400>,
			<5200 5000 4800 4600 4400 4200>,
			<4000 3800 3600 3400 3200 3000>,
			<2800 2600 2400 2200 2000 1800>,
			<1600 1400 1200 1000 900 800>,
			<700 600 500 400 300 200>,
			<100 0>;
		qcom,lut-data = <6271 5713 5390 5160 5091 5086 5074>,
			<6297 5720 5394 5161 5091 5086 5075>,
			<6320 5728 5399 5162 5092 5087 5076>,
			<6340 5738 5404 5164 5094 5089 5077>,
			<6353 5746 5407 5165 5095 5090 5079>,
			<6360 5751 5409 5167 5097 5092 5081>,
			<6359 5751 5409 5168 5099 5094 5082>,
			<6350 5749 5408 5170 5101 5096 5084>,
			<6343 5748 5407 5173 5103 5098 5086>,
			<6364 5749 5408 5176 5106 5101 5088>,
			<6413 5750 5410 5180 5108 5103 5091>,
			<6434 5752 5414 5185 5112 5107 5094>,
			<6388 5773 5423 5189 5115 5110 5097>,
			<6322 5799 5435 5193 5120 5114 5100>,
			<6302 5802 5438 5199 5124 5118 5104>,
			<6300 5776 5439 5208 5131 5124 5109>,
			<6298 5744 5439 5214 5136 5129 5113>,
			<6284 5720 5426 5216 5139 5132 5116>,
			<6251 5698 5393 5216 5141 5134 5118>,
			<6229 5680 5365 5213 5140 5134 5119>,
			<6224 5666 5351 5190 5124 5118 5105>,
			<6221 5655 5340 5163 5101 5096 5085>,
			<6221 5646 5335 5157 5094 5090 5079>,
			<6240 5638 5333 5156 5094 5090 5079>,
			<6269 5633 5332 5156 5094 5090 5080>,
			<6296 5632 5332 5158 5096 5092 5081>,
			<6323 5634 5334 5161 5100 5095 5084>,
			<6352 5636 5335 5164 5105 5100 5087>,
			<6385 5647 5336 5168 5109 5104 5091>,
			<6422 5674 5337 5172 5114 5109 5096>,
			<6459 5704 5338 5177 5119 5113 5100>,
			<6495 5736 5340 5183 5124 5118 5105>,
			<6534 5771 5343 5188 5128 5122 5109>,
			<6578 5807 5350 5189 5128 5122 5109>,
			<6631 5841 5368 5190 5123 5117 5102>,
			<6688 5878 5390 5189 5117 5110 5094>,
			<6743 5920 5413 5184 5111 5105 5090>,
			<6800 5967 5438 5177 5104 5099 5087>,
			<6859 6015 5464 5175 5102 5098 5087>,
			<6919 6063 5488 5179 5103 5099 5088>,
			<6983 6113 5513 5186 5105 5101 5090>,
			<7064 6173 5543 5191 5105 5101 5090>,
			<7163 6240 5576 5196 5101 5096 5084>,
			<7295 6324 5618 5203 5098 5092 5079>,
			<7482 6441 5674 5219 5103 5098 5086>,
			<7806 6617 5756 5247 5123 5119 5110>,
			<8064 6734 5809 5268 5133 5129 5120>,
			<8539 6875 5879 5302 5146 5140 5126>,
			<9499 7066 5966 5331 5157 5149 5129>,
			<10966 7350 6066 5339 5161 5151 5129>,
			<13200 7887 6184 5330 5146 5137 5117>,
			<17845 9127 6337 5308 5132 5125 5108>,
			<26941 11294 6518 5292 5134 5127 5112>,
			<56456 17656 7089 5336 5156 5152 5143>,
			<56456 17656 7089 5336 5156 5152 5143>,
			<56456 17656 7089 5336 5156 5152 5143>;
	};
};
